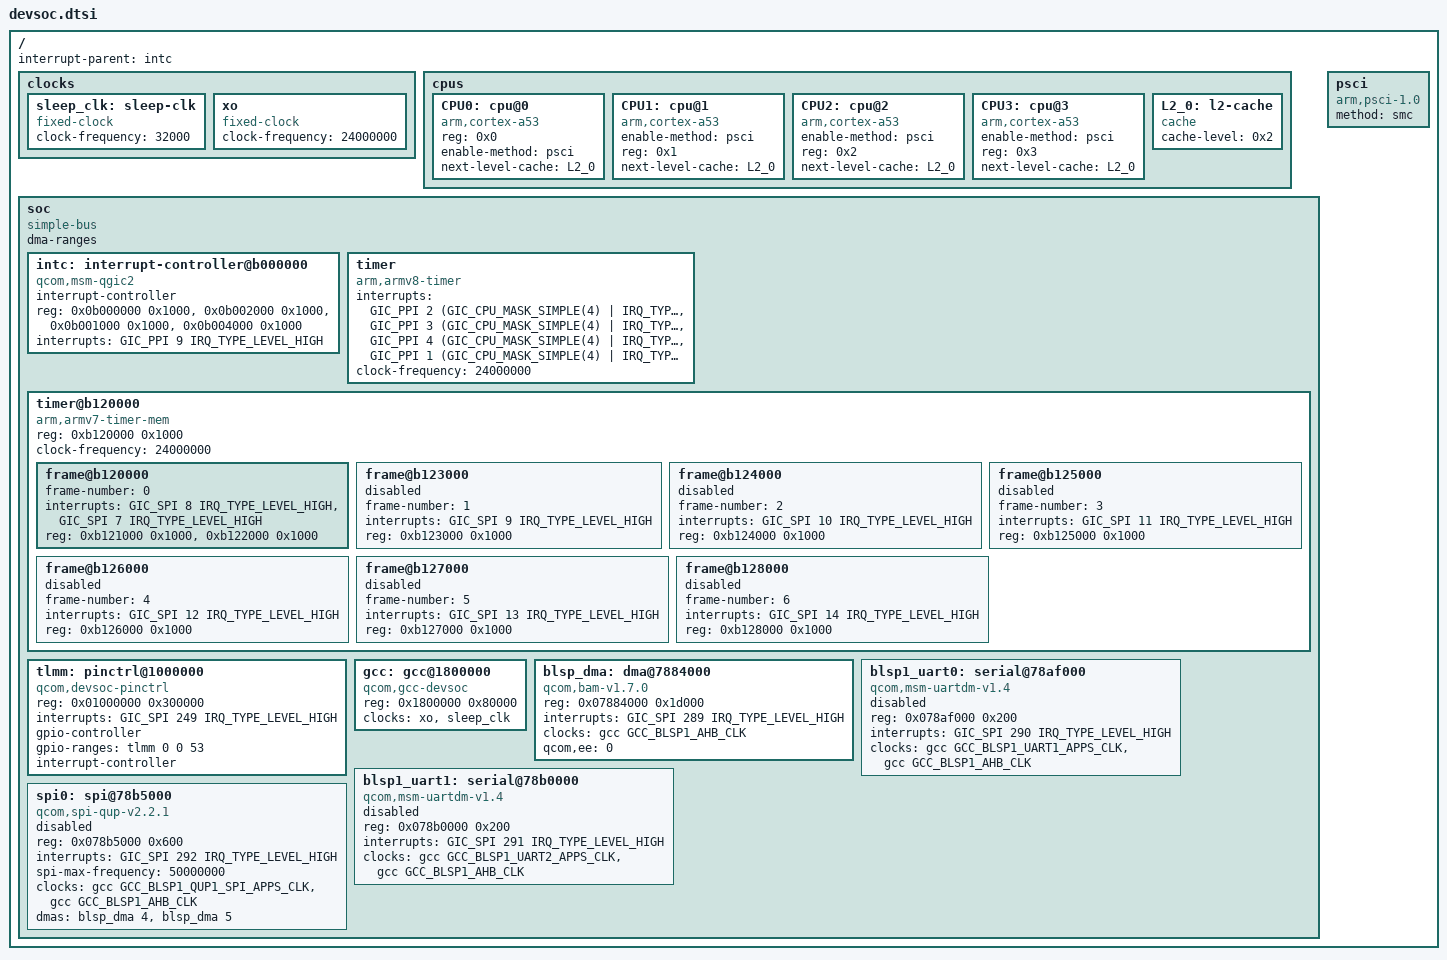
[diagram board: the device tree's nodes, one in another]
// SPDX-License-Identifier: (GPL-2.0+ OR BSD-3-Clause)
/*
 * Dev SoC device tree source
 *
 * Copyright (c) 2020-2021 The Linux Foundation. All rights reserved.
 * Copyright (c) 2022 Qualcomm Innovation Center, Inc. All rights reserved.
 */

#include <dt-bindings/interrupt-controller/arm-gic.h>
#include <dt-bindings/clock/qcom,gcc-devsoc.h>
#include <dt-bindings/reset/qcom,gcc-devsoc.h>


/ {
	#address-cells = <2>;
	#size-cells = <2>;
	interrupt-parent = <&intc>;

	clocks {
		sleep_clk: sleep-clk {
			compatible = "fixed-clock";
			clock-frequency = <32000>;
			#clock-cells = <0>;
		};

		xo: xo {
			compatible = "fixed-clock";
			clock-frequency = <24000000>;
			#clock-cells = <0>;
		};
	};

	cpus: cpus {
		#address-cells = <1>;
		#size-cells = <0>;

		CPU0: cpu@0 {
			device_type = "cpu";
			compatible = "arm,cortex-a53";
			reg = <0x0>;
			enable-method = "psci";
			next-level-cache = <&L2_0>;
		};

		CPU1: cpu@1 {
			device_type = "cpu";
			compatible = "arm,cortex-a53";
			enable-method = "psci";
			reg = <0x1>;
			next-level-cache = <&L2_0>;
		};

		CPU2: cpu@2 {
			device_type = "cpu";
			compatible = "arm,cortex-a53";
			enable-method = "psci";
			reg = <0x2>;
			next-level-cache = <&L2_0>;
		};

		CPU3: cpu@3 {
			device_type = "cpu";
			compatible = "arm,cortex-a53";
			enable-method = "psci";
			reg = <0x3>;
			next-level-cache = <&L2_0>;
		};

		L2_0: l2-cache {
			compatible = "cache";
			cache-level = <0x2>;
		};
	};

	soc: soc {
		#address-cells = <1>;
		#size-cells = <1>;
		ranges = <0 0 0 0xffffffff>;
		dma-ranges;
		compatible = "simple-bus";

		intc: interrupt-controller@b000000 {
			compatible = "qcom,msm-qgic2";
			interrupt-controller;
			#interrupt-cells = <0x3>;
			reg = <0x0b000000 0x1000>,  /*GICD*/
				<0x0b002000 0x1000>,  /*GICC*/
				<0x0b001000 0x1000>,  /*GICH*/
				<0x0b004000 0x1000>;  /*GICV*/
			interrupts = <GIC_PPI 9 IRQ_TYPE_LEVEL_HIGH>;
		};

		timer {
			compatible = "arm,armv8-timer";
			interrupts = <GIC_PPI 2 (GIC_CPU_MASK_SIMPLE(4) | IRQ_TYPE_LEVEL_LOW)>,
				<GIC_PPI 3 (GIC_CPU_MASK_SIMPLE(4) | IRQ_TYPE_LEVEL_LOW)>,
				<GIC_PPI 4 (GIC_CPU_MASK_SIMPLE(4) | IRQ_TYPE_LEVEL_LOW)>,
				<GIC_PPI 1 (GIC_CPU_MASK_SIMPLE(4) | IRQ_TYPE_LEVEL_LOW)>;
			clock-frequency = <24000000>;
		};

		timer@b120000 {
			#address-cells = <1>;
			#size-cells = <1>;
			ranges;
			compatible = "arm,armv7-timer-mem";
			reg = <0xb120000 0x1000>;
			clock-frequency = <24000000>;

			frame@b120000 {
				frame-number = <0>;
				interrupts = <GIC_SPI 8 IRQ_TYPE_LEVEL_HIGH>,
					     <GIC_SPI 7 IRQ_TYPE_LEVEL_HIGH>;
				reg = <0xb121000 0x1000>,
				      <0xb122000 0x1000>;
			};

			frame@b123000 {
				frame-number = <1>;
				interrupts = <GIC_SPI 9 IRQ_TYPE_LEVEL_HIGH>;
				reg = <0xb123000 0x1000>;
				status = "disabled";
			};

			frame@b124000 {
				frame-number = <2>;
				interrupts = <GIC_SPI 10 IRQ_TYPE_LEVEL_HIGH>;
				reg = <0xb124000 0x1000>;
				status = "disabled";
			};

			frame@b125000 {
				frame-number = <3>;
				interrupts = <GIC_SPI 11 IRQ_TYPE_LEVEL_HIGH>;
				reg = <0xb125000 0x1000>;
				status = "disabled";
			};

			frame@b126000 {
				frame-number = <4>;
				interrupts = <GIC_SPI 12 IRQ_TYPE_LEVEL_HIGH>;
				reg = <0xb126000 0x1000>;
				status = "disabled";
			};

			frame@b127000 {
				frame-number = <5>;
				interrupts = <GIC_SPI 13 IRQ_TYPE_LEVEL_HIGH>;
				reg = <0xb127000 0x1000>;
				status = "disabled";
			};

			frame@b128000 {
				frame-number = <6>;
				interrupts = <GIC_SPI 14 IRQ_TYPE_LEVEL_HIGH>;
				reg = <0xb128000 0x1000>;
				status = "disabled";
			};
		};

		tlmm: pinctrl@1000000 {
			compatible = "qcom,devsoc-pinctrl";
			reg = <0x01000000 0x300000>;
			interrupts = <GIC_SPI 249 IRQ_TYPE_LEVEL_HIGH>;
			gpio-controller;
			#gpio-cells = <2>;
			gpio-ranges = <&tlmm 0 0 53>;
			interrupt-controller;
			#interrupt-cells = <2>;
		};

		gcc: gcc@1800000 {
			compatible = "qcom,gcc-devsoc";
			reg = <0x1800000 0x80000>;
			clocks = <&xo>, <&sleep_clk>;
			clock-names = "xo", "sleep_clk";
			#clock-cells = <0x1>;
			#reset-cells = <0x1>;
		};

		blsp_dma: dma@7884000 {
			compatible = "qcom,bam-v1.7.0";
			reg = <0x07884000 0x1d000>;
			interrupts = <GIC_SPI 289 IRQ_TYPE_LEVEL_HIGH>;
			clocks = <&gcc GCC_BLSP1_AHB_CLK>;
			clock-names = "bam_clk";
			#dma-cells = <1>;
			qcom,ee = <0>;
		};

		blsp1_uart0: serial@78af000 {
			compatible = "qcom,msm-uartdm-v1.4", "qcom,msm-uartdm";
			reg = <0x078af000 0x200>;
			interrupts = <GIC_SPI 290 IRQ_TYPE_LEVEL_HIGH>;
			clocks = <&gcc GCC_BLSP1_UART1_APPS_CLK>,
				 <&gcc GCC_BLSP1_AHB_CLK>;
			clock-names = "core", "iface";
			status = "disabled";
		};

		blsp1_uart1: serial@78b0000 {
			compatible = "qcom,msm-uartdm-v1.4", "qcom,msm-uartdm";
			reg = <0x078b0000 0x200>;
			interrupts = <GIC_SPI 291 IRQ_TYPE_LEVEL_HIGH>;
			clocks = <&gcc GCC_BLSP1_UART2_APPS_CLK>,
				 <&gcc GCC_BLSP1_AHB_CLK>;
			clock-names = "core", "iface";
			status = "disabled";
		};

		spi0: spi@78b5000 {
			compatible = "qcom,spi-qup-v2.2.1";
			#address-cells = <1>;
			#size-cells = <0>;
			reg = <0x078b5000 0x600>;
			interrupts = <GIC_SPI 292 IRQ_TYPE_LEVEL_HIGH>;
			spi-max-frequency = <50000000>;
			clocks = <&gcc GCC_BLSP1_QUP1_SPI_APPS_CLK>,
				<&gcc GCC_BLSP1_AHB_CLK>;
			clock-names = "core", "iface";
			dmas = <&blsp_dma 4>, <&blsp_dma 5>;
			dma-names = "tx", "rx";
			status = "disabled";
		};
	};

	psci {
		compatible = "arm,psci-1.0";
		method = "smc";
	};
};
